# SF32LB55x register map
File version: 1.0
CPU: CM33 r0p1, little endian, MPU, FPU, 3 interrupt priority bits
Registers are 32-bit, read-write, reset 0x0 unless marked. A register's access mark holds for its fields unless they carry their own. Offsets are from the block's base; [hi:lo] are bit positions; {n}, {i} and the like mark numbered series.

## HPSYS_RCC
Base 0x40000000
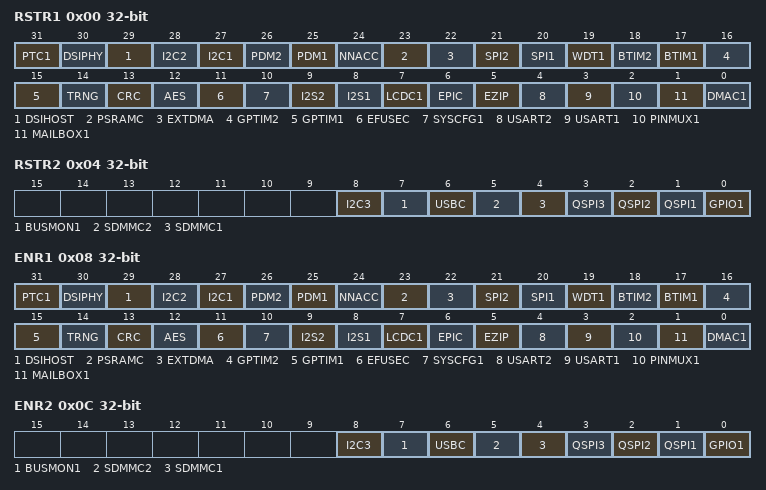
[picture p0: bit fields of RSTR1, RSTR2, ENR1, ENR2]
0x00 RSTR1 — Reset Register 1
  [31] PTC1 — 0 - no reset; 1 - reset
  [30] DSIPHY — 0 - no reset; 1 - reset
  [29] DSIHOST — 0 - no reset; 1 - reset
  [28] I2C2 — 0 - no reset; 1 - reset
  [27] I2C1 — 0 - no reset; 1 - reset
  [26] PDM2 — 0 - no reset; 1 - reset
  [25] PDM1 — 0 - no reset; 1 - reset
  [24] NNACC — 0 - no reset; 1 - reset
  [23] PSRAMC — 0 - no reset; 1 - reset
  [22] EXTDMA — 0 - no reset; 1 - reset
  [21] SPI2 — 0 - no reset; 1 - reset
  [20] SPI1 — 0 - no reset; 1 - reset
  [19] WDT1 — 0 - no reset; 1 - reset
  [18] BTIM2 — 0 - no reset; 1 - reset
  [17] BTIM1 — 0 - no reset; 1 - reset
  [16] GPTIM2 — 0 - no reset; 1 - reset
  [15] GPTIM1 — 0 - no reset; 1 - reset
  [14] TRNG — 0 - no reset; 1 - reset
  [13] CRC — 0 - no reset; 1 - reset
  [12] AES — 0 - no reset; 1 - reset
  [11] EFUSEC — 0 - no reset; 1 - reset
  [10] SYSCFG1 — 0 - no reset; 1 - reset
  [9] I2S2 — 0 - no reset; 1 - reset
  [8] I2S1 — 0 - no reset; 1 - reset
  [7] LCDC1 — 0 - no reset; 1 - reset
  [6] EPIC — 0 - no reset; 1 - reset
  [5] EZIP — 0 - no reset; 1 - reset
  [4] USART2 — 0 - no reset; 1 - reset
  [3] USART1 — 0 - no reset; 1 - reset
  [2] PINMUX1 — 0 - no reset; 1 - reset
  [1] MAILBOX1 — 0 - no reset; 1 - reset
  [0] DMAC1 — 0 - no reset; 1 - reset
0x04 RSTR2 — Reset Register 2
  [8] I2C3 — 0 - no reset; 1 - reset
  [7] BUSMON1 — 0 - no reset; 1 - reset
  [6] USBC — 0 - no reset; 1 - reset
  [5] SDMMC2 — 0 - no reset; 1 - reset
  [4] SDMMC1 — 0 - no reset; 1 - reset
  [3] QSPI3 — 0 - no reset; 1 - reset
  [2] QSPI2 — 0 - no reset; 1 - reset
  [1] QSPI1 — 0 - no reset; 1 - reset
  [0] GPIO1 — 0 - no reset; 1 - reset
0x08 ENR1 — Enable Register 1
  [31] PTC1 — 0 - disabled; 1 - enabled
  [30] DSIPHY — 0 - disabled; 1 - enabled
  [29] DSIHOST — 0 - disabled; 1 - enabled
  [28] I2C2 — 0 - disabled; 1 - enabled
  [27] I2C1 — 0 - disabled; 1 - enabled
  [26] PDM2 — 0 - disabled; 1 - enabled
  [25] PDM1 — 0 - disabled; 1 - enabled
  [24] NNACC — 0 - disabled; 1 - enabled
  [23] PSRAMC — 0 - disabled; 1 - enabled
  [22] EXTDMA — 0 - disabled; 1 - enabled
  [21] SPI2 — 0 - disabled; 1 - enabled
  [20] SPI1 — 0 - disabled; 1 - enabled
  [19] WDT1 — 0 - disabled; 1 - enabled
  [18] BTIM2 — 0 - disabled; 1 - enabled
  [17] BTIM1 — 0 - disabled; 1 - enabled
  [16] GPTIM2 — 0 - disabled; 1 - enabled
  [15] GPTIM1 — 0 - disabled; 1 - enabled
  [14] TRNG — 0 - disabled; 1 - enabled
  [13] CRC — 0 - disabled; 1 - enabled
  [12] AES — 0 - disabled; 1 - enabled
  [11] EFUSEC — 0 - disabled; 1 - enabled
  [10] SYSCFG1 — 0 - disabled; 1 - enabled
  [9] I2S2 — 0 - disabled; 1 - enabled
  [8] I2S1 — 0 - disabled; 1 - enabled
  [7] LCDC1 — 0 - disabled; 1 - enabled
  [6] EPIC — 0 - disabled; 1 - enabled
  [5] EZIP — 0 - disabled; 1 - enabled
  [4] USART2 — 0 - disabled; 1 - enabled
  [3] USART1 — 0 - disabled; 1 - enabled
  [2] PINMUX1 — 0 - disabled; 1 - enabled
  [1] MAILBOX1 — 0 - disabled; 1 - enabled
  [0] DMAC1 — 0 - disabled; 1 - enabled
0x0C ENR2 — Enable Register 2
  [8] I2C3 — 0 - disabled; 1 - enabled
  [7] BUSMON1 — 0 - disabled; 1 - enabled
  [6] USBC — 0 - disabled; 1 - enabled
  [5] SDMMC2 — 0 - disabled; 1 - enabled
  [4] SDMMC1 — 0 - disabled; 1 - enabled
  [3] QSPI3 — 0 - disabled; 1 - enabled
  [2] QSPI2 — 0 - disabled; 1 - enabled
  [1] QSPI1 — 0 - disabled; 1 - enabled
  [0] GPIO1 — 0 - disabled; 1 - enabled
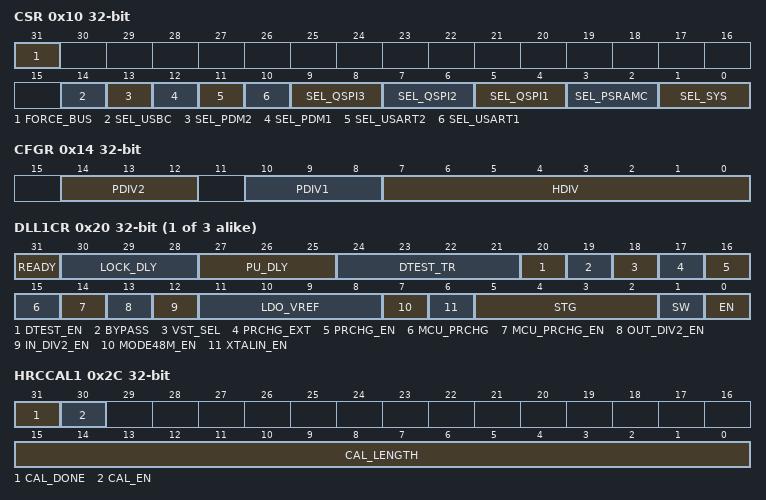
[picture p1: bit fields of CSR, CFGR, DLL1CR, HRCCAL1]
0x10 CSR — Clock Select Register
  [31] FORCE_BUS — for debug only
  [14] SEL_USBC — select USB source clock 0 - clk_sys; 1 - dll3
  [13] SEL_PDM2 — 0 - clk_sys; 1 - dll2
  [12] SEL_PDM1 — 0 - clk_sys; 1 - dll2
  [11] SEL_USART2 — 0 - hrc48; 1 - hxt48
  [10] SEL_USART1 — 0 - hrc48; 1 - hxt48
  [9:8] SEL_QSPI3 — selet QSPI3 function clock 0 - clk_sys; 1 - reserved; 2 - dll2; 3 - dll3
  [7:6] SEL_QSPI2 — selet QSPI2 function clock 0 - clk_sys; 1 - reserved; 2 - dll2; 3 - dll3
  [5:4] SEL_QSPI1 — selet QSPI1 function clock 0 - clk_sys; 1 - reserved; 2 - dll2; 3 - dll3
  [3:2] SEL_PSRAMC — selet PSRAMC function clock 0 - clk_sys; 1 - reserved; 2 - dll2; 3 - dll3
  [1:0] SEL_SYS — select clk_sys source 0 - hrc48; 1 - hxt48; 2 - clk_lp; 3 - dll1
0x14 CFGR — Clock Configuration Register
  [14:12] PDIV2 — pclk2 = hclk / (2^PDIV2), by default divided by 32
  [10:8] PDIV1 — pclk1 = hclk / (2^PDIV1), by default divided by 2
  [7:0] HDIV — hclk = clk_sys / HDIV if HDIV=0, hclk = clk_sys
0x18 I2SR — I2S Register
  [4:0] DIV — I2S clock = pclk1 / DIV. After divider, I2S clock must be 12MHz.
0x1C USBCR — USBC Register
  [2:0] DIV — USB function clock is USB source clock divided by DIV. After divider, USB function clock must be 60MHz.
{0x1C+4i} DLL{i}CR (i=1..3) — DLL{i} Control Register
  [31] READY — 0: dll not ready 1: dll ready
  [30:28] LOCK_DLY
  [27:25] PU_DLY
  [24:21] DTEST_TR
  [20] DTEST_EN
  [19] BYPASS
  [18] VST_SEL
  [17] PRCHG_EXT
  [16] PRCHG_EN
  [15] MCU_PRCHG
  [14] MCU_PRCHG_EN
  [13] OUT_DIV2_EN — 0: dll output not divided 1: dll output divided by 2
  [12] IN_DIV2_EN
  [11:8] LDO_VREF
  [7] MODE48M_EN
  [6] XTALIN_EN
  [5:2] STG — DLL lock freqency is decided by STG. DLL output frequency is: 0: 192MHz(if OUT_DIV2_EN=1) or 384MHz(if OUT_DIV2_EN=0) 1: 168MHz(if OUT_DIV2_EN=1) or 336MHz(if OUT_DIV2_EN=0) 2: 144MHz(if OUT_DIV2_EN=1) or 288MHz(if OUT_DIV2_EN=0) 3: 120MHz(if OUT_DIV2_EN=1) or 240MHz(if OUT_DIV2_EN=0) 4: 96MHz(if OUT_DIV2_EN=1) or 192MHz(if OUT_DIV2_EN=0)
  [1] SW
  [0] EN — 0: dll disabled 1: dll enabled
0x2C HRCCAL1 — HRC Calibration Register 1
  [31] CAL_DONE — Calibration done. After a new calibration started, results should be processed only when cal_done asserted.
  [30] CAL_EN — Calibration enble. Set to 0 to clear result, then set to 1 to start a new calibration
  [15:0] CAL_LENGTH — Target hxt48 cycles during calibration
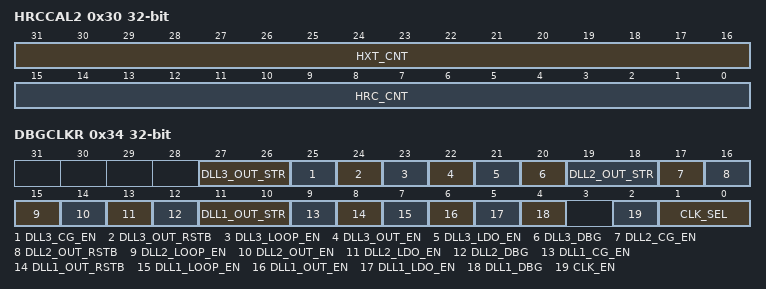
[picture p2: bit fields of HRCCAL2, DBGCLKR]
0x30 HRCCAL2 — HRC Calibration Register 2
  [31:16] HXT_CNT — Total hxt48 cycles during calibration
  [15:0] HRC_CNT — Total hrc48 cycles during calibration
0x34 DBGCLKR — Debug Clock Register
  [27:26] DLL3_OUT_STR — for debug only
  [25] DLL3_CG_EN — for debug only
  [24] DLL3_OUT_RSTB — for debug only
  [23] DLL3_LOOP_EN — for debug only
  [22] DLL3_OUT_EN — for debug only
  [21] DLL3_LDO_EN — for debug only
  [20] DLL3_DBG — for debug only
  [19:18] DLL2_OUT_STR — for debug only
  [17] DLL2_CG_EN — for debug only
  [16] DLL2_OUT_RSTB — for debug only
  [15] DLL2_LOOP_EN — for debug only
  [14] DLL2_OUT_EN — for debug only
  [13] DLL2_LDO_EN — for debug only
  [12] DLL2_DBG — for debug only
  [11:10] DLL1_OUT_STR — for debug only
  [9] DLL1_CG_EN — for debug only
  [8] DLL1_OUT_RSTB — for debug only
  [7] DLL1_LOOP_EN — for debug only
  [6] DLL1_OUT_EN — for debug only
  [5] DLL1_LDO_EN — for debug only
  [4] DLL1_DBG — for debug only
  [2] CLK_EN — for debug only
  [1:0] CLK_SEL — for debug only
